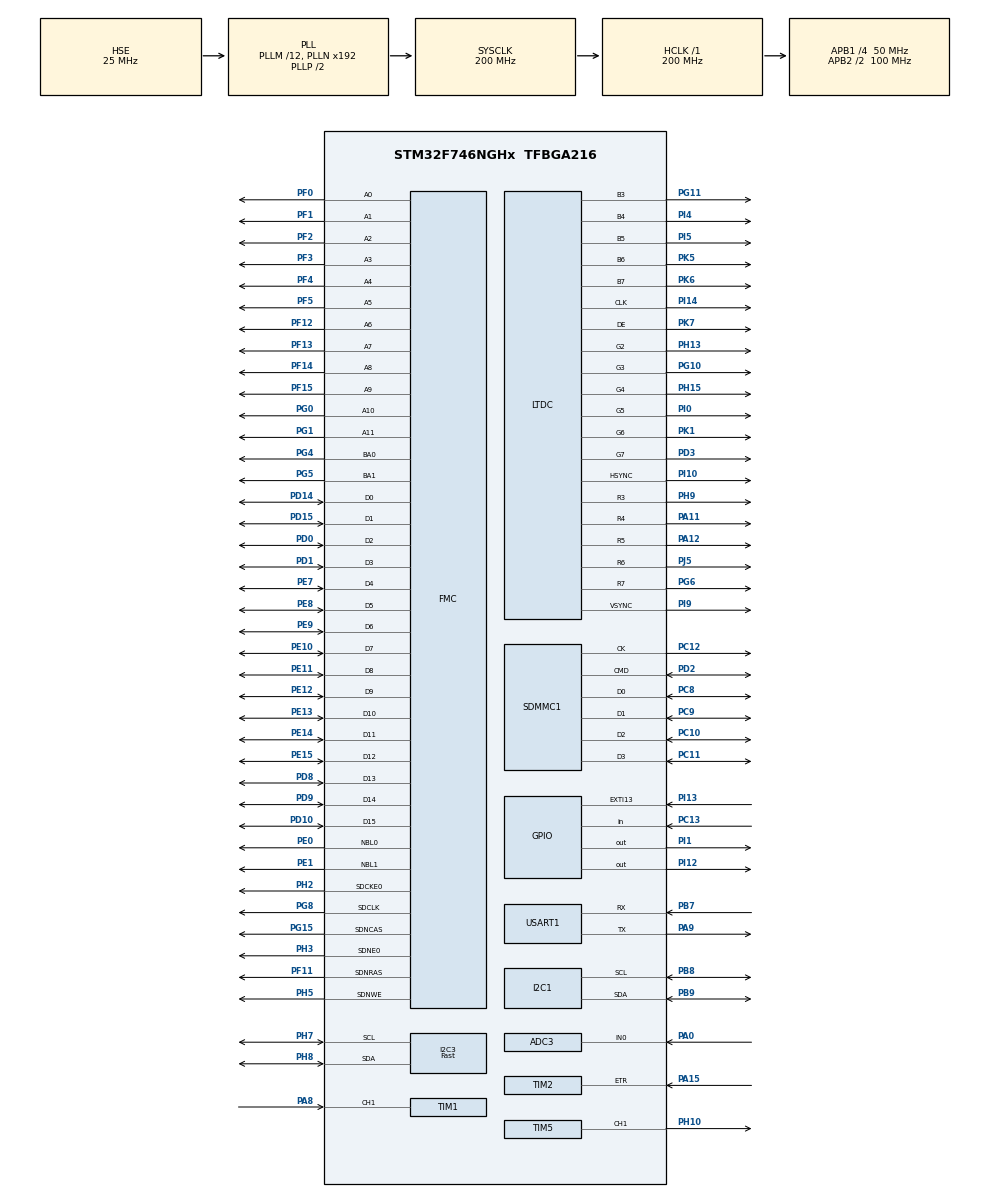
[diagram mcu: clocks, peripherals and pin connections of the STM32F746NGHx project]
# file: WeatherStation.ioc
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ADC3.Channel-0\#ChannelRegularConversion=ADC_CHANNEL_0
ADC3.ContinuousConvMode=ENABLE
ADC3.EOCSelection=ADC_EOC_SEQ_CONV
ADC3.NbrOfConversionFlag=1
ADC3.Rank-0\#ChannelRegularConversion=1
ADC3.SamplingTime-0\#ChannelRegularConversion=ADC_SAMPLETIME_3CYCLES
CORTEX_M7.ART_ACCLERATOR_ENABLE=1
Dma.Request0=SDMMC1_RX
Dma.Request1=SDMMC1_TX
Dma.SDMMC1_RX.0.Direction=DMA_PERIPH_TO_MEMORY
Dma.SDMMC1_RX.0.FIFOMode=DMA_FIFOMODE_ENABLE
Dma.SDMMC1_RX.0.FIFOThreshold=DMA_FIFO_THRESHOLD_FULL
Dma.SDMMC1_RX.0.Instance=DMA2_Stream3
Dma.SDMMC1_RX.0.MemBurst=DMA_MBURST_INC4
Dma.SDMMC1_RX.0.MemDataAlignment=DMA_MDATAALIGN_WORD
Dma.SDMMC1_RX.0.MemInc=DMA_MINC_ENABLE
Dma.SDMMC1_RX.0.Mode=DMA_PFCTRL
Dma.SDMMC1_RX.0.PeriphBurst=DMA_PBURST_INC4
Dma.SDMMC1_RX.0.PeriphDataAlignment=DMA_PDATAALIGN_WORD
Dma.SDMMC1_RX.0.PeriphInc=DMA_PINC_DISABLE
Dma.SDMMC1_RX.0.Priority=DMA_PRIORITY_LOW
Dma.SDMMC1_TX.1.Direction=DMA_MEMORY_TO_PERIPH
Dma.SDMMC1_TX.1.FIFOMode=DMA_FIFOMODE_ENABLE
Dma.SDMMC1_TX.1.FIFOThreshold=DMA_FIFO_THRESHOLD_FULL
Dma.SDMMC1_TX.1.Instance=DMA2_Stream6
Dma.SDMMC1_TX.1.MemBurst=DMA_MBURST_INC4
Dma.SDMMC1_TX.1.MemDataAlignment=DMA_MDATAALIGN_WORD
Dma.SDMMC1_TX.1.MemInc=DMA_MINC_ENABLE
Dma.SDMMC1_TX.1.Mode=DMA_PFCTRL
Dma.SDMMC1_TX.1.PeriphBurst=DMA_PBURST_INC4
Dma.SDMMC1_TX.1.PeriphDataAlignment=DMA_PDATAALIGN_WORD
Dma.SDMMC1_TX.1.PeriphInc=DMA_PINC_DISABLE
Dma.SDMMC1_TX.1.Priority=DMA_PRIORITY_LOW
FATFS.BSP.number=1
FATFS.USE_DMA_CODE_SD=1
FATFS0.BSP.STBoard=false
FATFS0.BSP.api=Unknown
FATFS0.BSP.i2caddr=0
FATFS0.BSP.instance=PC13
FATFS0.BSP.ip=GPIO
FATFS0.BSP.mode=Input
FATFS0.BSP.name=Detect_SDIO
FATFS0.BSP.solution=PC13
I2C1.Timing=0x00C0EAFF
I2C3.I2C_Speed_Mode=I2C_Fast
I2C3.Timing=0x00401959
Mcu.Family=STM32F7
Mcu.Name=STM32F746NGHx
Mcu.Package=TFBGA216
NVIC.DMA2_Stream3_IRQn=true\:0\:0\:false\:false\:true\:false\:true
NVIC.DMA2_Stream6_IRQn=true\:0\:0\:false\:false\:true\:false\:true
NVIC.EXTI15_10_IRQn=true\:11\:0\:true\:false\:true\:true\:true
NVIC.I2C3_EV_IRQn=true\:5\:0\:true\:false\:true\:true\:true
NVIC.PriorityGroup=NVIC_PRIORITYGROUP_4
NVIC.RTC_Alarm_IRQn=true\:14\:0\:true\:false\:true\:true\:true
NVIC.SDMMC1_IRQn=true\:0\:0\:false\:false\:true\:true\:true
NVIC.TIM1_CC_IRQn=true\:1\:0\:true\:false\:true\:true\:true
NVIC.TIM5_IRQn=true\:10\:0\:true\:false\:true\:true\:true
PA0/WKUP.Signal=ADCx_IN0
PA11.Mode=RGB565
PA11.Signal=LTDC_R4
PA12.Mode=RGB565
PA12.Signal=LTDC_R5
PA13.Mode=Serial_Wire
PA13.Signal=SYS_JTMS-SWDIO
PA14.Mode=Serial_Wire
PA14.Signal=SYS_JTCK-SWCLK
PA15.GPIO_PuPd=GPIO_PULLUP
PA15.Signal=S_TIM2_CH1_ETR
PA8.GPIO_PuPd=GPIO_PULLUP
PA8.Signal=S_TIM1_CH1
PA9.Mode=Asynchronous
PA9.Signal=USART1_TX
PB7.Mode=Asynchronous
PB7.Signal=USART1_RX
PB8.Mode=I2C
PB8.Signal=I2C1_SCL
PB9.Mode=I2C
PB9.Signal=I2C1_SDA
PC10.Mode=SD_4_bits_Wide_bus
PC10.Signal=SDMMC1_D2
PC11.Mode=SD_4_bits_Wide_bus
PC11.Signal=SDMMC1_D3
PC12.Mode=SD_4_bits_Wide_bus
PC12.Signal=SDMMC1_CK
PC13.Signal=GPIO_Input
PC8.Mode=SD_4_bits_Wide_bus
PC8.Signal=SDMMC1_D0
PC9.Mode=SD_4_bits_Wide_bus
PC9.Signal=SDMMC1_D1
PD0.Signal=FMC_D2_DA2
PD1.Signal=FMC_D3_DA3
PD10.Signal=FMC_D15_DA15
PD14.Signal=FMC_D0_DA0
PD15.Signal=FMC_D1_DA1
PD2.Mode=SD_4_bits_Wide_bus
PD2.Signal=SDMMC1_CMD
PD3.Mode=RGB565
PD3.Signal=LTDC_G7
PD8.Signal=FMC_D13_DA13
PD9.Signal=FMC_D14_DA14
PE0.Signal=FMC_NBL0
PE1.Signal=FMC_NBL1
PE10.Signal=FMC_D7_DA7
PE11.Signal=FMC_D8_DA8
PE12.Signal=FMC_D9_DA9
PE13.Signal=FMC_D10_DA10
PE14.Signal=FMC_D11_DA11
PE15.Signal=FMC_D12_DA12
PE7.Signal=FMC_D4_DA4
PE8.Signal=FMC_D5_DA5
PE9.Signal=FMC_D6_DA6
PF0.Signal=FMC_A0
PF1.Signal=FMC_A1
PF11.Signal=FMC_SDNRAS
PF12.Signal=FMC_A6
PF13.Signal=FMC_A7
PF14.Signal=FMC_A8
PF15.Signal=FMC_A9
PF2.Signal=FMC_A2
PF3.Signal=FMC_A3
PF4.Signal=FMC_A4
PF5.Signal=FMC_A5
PG0.Signal=FMC_A10
PG1.Signal=FMC_A11
PG10.Mode=RGB565
PG10.Signal=LTDC_G3
PG11.Mode=RGB565
PG11.Signal=LTDC_B3
PG15.Signal=FMC_SDNCAS
PG4.Signal=FMC_A14_BA0
PG5.Signal=FMC_A15_BA1
PG6.Mode=RGB565
PG6.Signal=LTDC_R7
PG8.Signal=FMC_SDCLK
PH0/OSC_IN.Mode=HSE-External-Oscillator
PH0/OSC_IN.Signal=RCC_OSC_IN
PH1/OSC_OUT.Mode=HSE-External-Oscillator
PH1/OSC_OUT.Signal=RCC_OSC_OUT
PH10.Signal=S_TIM5_CH1
PH13.Mode=RGB565
PH13.Signal=LTDC_G2
PH15.Mode=RGB565
PH15.Signal=LTDC_G4
PH2.Mode=SdramChipSelect1_1
PH2.Signal=FMC_SDCKE0
PH3.Mode=SdramChipSelect1_1
PH3.Signal=FMC_SDNE0
PH5.Signal=FMC_SDNWE
PH7.Mode=I2C
PH7.Signal=I2C3_SCL
PH8.Mode=I2C
PH8.Signal=I2C3_SDA
PH9.Mode=RGB565
PH9.Signal=LTDC_R3
PI0.Mode=RGB565
PI0.Signal=LTDC_G5
PI1.Signal=GPIO_Output
PI10.Mode=RGB565
PI10.Signal=LTDC_HSYNC
PI12.PinState=GPIO_PIN_SET
PI12.Signal=GPIO_Output
PI13.Signal=GPXTI13
PI14.Mode=RGB565
PI14.Signal=LTDC_CLK
PI4.Mode=RGB565
PI4.Signal=LTDC_B4
PI5.Mode=RGB565
PI5.Signal=LTDC_B5
PI9.Mode=RGB565
PI9.Signal=LTDC_VSYNC
PJ5.Mode=RGB565
PJ5.Signal=LTDC_R6
PK1.Mode=RGB565
PK1.Signal=LTDC_G6
PK5.Mode=RGB565
PK5.Signal=LTDC_B6
PK6.Mode=RGB565
PK6.Signal=LTDC_B7
PK7.Mode=RGB565
PK7.Signal=LTDC_DE
ProjectManager.HeapSize=0x200
ProjectManager.StackSize=0x400
ProjectManager.TargetToolchain=STM32CubeIDE
RCC.AHBFreq_Value=200000000
RCC.APB1CLKDivider=RCC_HCLK_DIV4
RCC.APB1Freq_Value=50000000
RCC.APB1TimFreq_Value=100000000
RCC.APB2CLKDivider=RCC_HCLK_DIV2
RCC.APB2Freq_Value=100000000
RCC.APB2TimFreq_Value=200000000
RCC.CortexFreq_Value=200000000
RCC.HCLKFreq_Value=200000000
RCC.HSE_VALUE=25000000
RCC.HSI_VALUE=16000000
RCC.LSE_VALUE=32768
RCC.PLLM=12
RCC.PLLQ=8
RCC.PLLSAIN=72
RCC.PLLSAIR=3
RCC.PLLSourceVirtual=RCC_PLLSOURCE_HSE
RCC.SDMMCClockSelection=RCC_SDMMC1CLKSOURCE_CLK48
RCC.SYSCLKFreq_VALUE=200000000
RCC.SYSCLKSource=RCC_SYSCLKSOURCE_PLLCLK
RCC.USBFreq_Value=50000000
RCC.VCOOutputFreq_Value=400000000
RTC.Alarm-Alarm\ A=RTC_ALARM_A
RTC.AlarmMaskDateWeekDay-Alarm\ A=RTC_ALARMMASK_DATEWEEKDAY
RTC.AlarmMaskHours-Alarm\ A=RTC_ALARMMASK_HOURS
RTC.AlarmMaskMinutes-Alarm\ A=RTC_ALARMMASK_MINUTES
RTC.Format=RTC_FORMAT_BIN
RTC.Minutes_A-Alarm\ A=0
RTC.Month=RTC_MONTH_JANUARY
RTC.Seconds_A-Alarm\ A=0
RTC.WeekDay=RTC_WEEKDAY_MONDAY
RTC.Year=21
SH.ADCx_IN0.0=ADC3_IN0,IN0
SH.FMC_A0.0=FMC_A0,12b-sda1
SH.FMC_A1.0=FMC_A1,12b-sda1
SH.FMC_A10.0=FMC_A10,12b-sda1
SH.FMC_A11.0=FMC_A11,12b-sda1
SH.FMC_A14_BA0.0=FMC_BA0,FourSdramBanks1
SH.FMC_A15_BA1.0=FMC_BA1,FourSdramBanks1
SH.FMC_A2.0=FMC_A2,12b-sda1
SH.FMC_A3.0=FMC_A3,12b-sda1
SH.FMC_A4.0=FMC_A4,12b-sda1
SH.FMC_A5.0=FMC_A5,12b-sda1
SH.FMC_A6.0=FMC_A6,12b-sda1
SH.FMC_A7.0=FMC_A7,12b-sda1
SH.FMC_A8.0=FMC_A8,12b-sda1
SH.FMC_A9.0=FMC_A9,12b-sda1
SH.FMC_D0_DA0.0=FMC_D0,sd-16b-d1
SH.FMC_D10_DA10.0=FMC_D10,sd-16b-d1
SH.FMC_D11_DA11.0=FMC_D11,sd-16b-d1
SH.FMC_D12_DA12.0=FMC_D12,sd-16b-d1
SH.FMC_D13_DA13.0=FMC_D13,sd-16b-d1
SH.FMC_D14_DA14.0=FMC_D14,sd-16b-d1
SH.FMC_D15_DA15.0=FMC_D15,sd-16b-d1
SH.FMC_D1_DA1.0=FMC_D1,sd-16b-d1
SH.FMC_D2_DA2.0=FMC_D2,sd-16b-d1
SH.FMC_D3_DA3.0=FMC_D3,sd-16b-d1
SH.FMC_D4_DA4.0=FMC_D4,sd-16b-d1
SH.FMC_D5_DA5.0=FMC_D5,sd-16b-d1
SH.FMC_D6_DA6.0=FMC_D6,sd-16b-d1
SH.FMC_D7_DA7.0=FMC_D7,sd-16b-d1
SH.FMC_D8_DA8.0=FMC_D8,sd-16b-d1
SH.FMC_D9_DA9.0=FMC_D9,sd-16b-d1
SH.FMC_NBL0.0=FMC_NBL0,Sd2ByteEnable1
SH.FMC_NBL1.0=FMC_NBL1,Sd2ByteEnable1
SH.FMC_SDCLK.0=FMC_SDCLK,12b-sda1
SH.FMC_SDNCAS.0=FMC_SDNCAS,12b-sda1
SH.FMC_SDNRAS.0=FMC_SDNRAS,12b-sda1
SH.FMC_SDNWE.0=FMC_SDNWE,12b-sda1
SH.S_TIM1_CH1.0=TIM1_CH1,Input_Capture1_from_TI1
SH.S_TIM2_CH1_ETR.0=TIM2_ETR,TriggerSource_ETR
SH.S_TIM5_CH1.0=TIM5_CH1,Output Compare1 CH1
TIM1.Channel-Input_Capture1_from_TI1=TIM_CHANNEL_1
TIM1.Period=10799
TIM1.Prescaler=29
TIM5.Channel-Output\ Compare1\ CH1=TIM_CHANNEL_1
TIM5.Period=999999
TIM5.Prescaler=999
USART1.VirtualMode-Asynchronous=VM_ASYNC
VP_DMA2D_VS_DMA2D.Mode=DMA2D_Activate
VP_FATFS_VS_SDIO.Mode=SDIO
VP_RTC_VS_RTC_Activate.Mode=RTC_Enabled
VP_RTC_VS_RTC_Alarm_A_Intern.Mode=Alarm A
VP_RTC_VS_RTC_Calendar.Mode=RTC_Calendar
VP_TIM1_VS_ClockSourceINT.Mode=Internal
VP_TIM2_VS_ControllerModeClock.Mode=Clock Mode
board=STM32F746G-DISCO

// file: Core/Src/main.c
/* USER CODE BEGIN Header */
/**
 ******************************************************************************
 * @file           : main.c
 * @brief          : Main program body
 ******************************************************************************
 * @attention
 *
 * <h2><center>&copy; Copyright (c) 2021 STMicroelectronics.
 * All rights reserved.</center></h2>
 *
 * This software component is licensed by ST under BSD 3-Clause license,
 * the "License"; You may not use this file except in compliance with the
 * License. You may obtain a copy of the License at:
 *                        opensource.org/licenses/BSD-3-Clause
 *
 * @author : Benjamin Chevais
 *
 ******************************************************************************
 */
/* USER CODE END Header */
#include <DrawFrameGraph.h>
#include <I2CSensors.h>
#include "main.h"
#include "adc.h"
#include "dma.h"
#include "dma2d.h"
#include "fatfs.h"
#include "i2c.h"
#include "ltdc.h"
#include "rtc.h"
#include "sdmmc.h"
#include "tim.h"
#include "usart.h"
#include "gpio.h"
#include "fmc.h"

/* USER CODE BEGIN Includes */

#include <stdio.h>
#include <string.h>
#include "WeatherStation.h"
#include "WindSpeed.h"
#include "WindDirection.h"
#include "Pressure.h"
#include "RainGauge.h"
#include "Sd.h"

#ifdef __GNUC__
/* With GCC/RAISONANCE, small printf (option LD Linker->Libraries->Small printf
set to 'Yes') calls __io_putchar() */
#define PUTCHAR_PROTOTYPE int __io_putchar(int ch)
#else
#define PUTCHAR_PROTOTYPE int fputc(int ch, FILE *f)
#endif /* __GNUC__ */
/* USER CODE END Includes */

/* USER CODE BEGIN PV */
int DELAY = 5;
double WIND_TICK = 0;
int alarmA_sdcard = 0;
acquisition_flag = 0; // define in main.h

RTC_DateTypeDef sDate;
RTC_TimeTypeDef sTime;

/* USER CODE END PV */

void SystemClock_Config(void);

int main(void)
{

  /* MCU Configuration--------------------------------------------------------*/

  /* Reset of all peripherals, Initializes the Flash interface and the Systick. */
  HAL_Init();

  /* Configure the system clock */
  SystemClock_Config();

  /* Initialize all configured peripherals */
  MX_GPIO_Init();
  MX_DMA2D_Init();
  MX_FMC_Init();
  MX_I2C3_Init();
  MX_LTDC_Init();
  MX_USART1_UART_Init();
  MX_I2C1_Init();
  MX_TIM5_Init();
  MX_ADC3_Init();
  MX_TIM1_Init();
  MX_TIM2_Init();
  MX_DMA_Init();
  MX_SDMMC1_SD_Init();
  MX_RTC_Init();
  MX_FATFS_Init();
  /* USER CODE BEGIN 2 */

	WeatherStationInit(); // initialize the global variables

	init_screen(); // Initialize the screen

	RaingaugeStart(&htim2); // Timer of rain
	HAL_TIM_OC_Start_IT(&htim5, TIM_CHANNEL_1); // Aggregation Timer
	HAL_TIM_IC_Start_IT(&htim1,TIM_CHANNEL_1); // Wind speed Timer
	HAL_RTC_Init(&hrtc); // RTC launch / AlarmA for the SD card
	HAL_ADC_Start(&hadc3); // Starts conversion Analog to Digital.
	initSD(); // Initialize the sd card

	printf("démarrage du programme !\r\n\n");

	display_home(); // Display the home screen

  /* USER CODE END 2 */

  /* Infinite loop */
	while (1)
	{

    /* USER CODE BEGIN 3 */
		HAL_RTC_GetDate(&hrtc, &sDate, RTC_FORMAT_BIN);
		HAL_RTC_GetTime(&hrtc, &sTime, RTC_FORMAT_BIN);

		if(acquisition_flag == 1) {
			aggregate();
			acquisition_flag = 0;
		}

		if(alarmA_sdcard == 1) {
			saveSD();
			alarmA_sdcard = 0;
		}
		/*
	  HAL_GPIO_TogglePin (GPIOI, GPIO_PIN_1);
	  HAL_Delay (1000);
		 */
	}
  /* USER CODE END 3 */
}

void SystemClock_Config(void)
{
  RCC_OscInitTypeDef RCC_OscInitStruct = {0};
  RCC_ClkInitTypeDef RCC_ClkInitStruct = {0};
  RCC_PeriphCLKInitTypeDef PeriphClkInitStruct = {0};

  /** Configure the main internal regulator output voltage
  */
  __HAL_RCC_PWR_CLK_ENABLE();
  __HAL_PWR_VOLTAGESCALING_CONFIG(PWR_REGULATOR_VOLTAGE_SCALE1);
  /** Initializes the RCC Oscillators according to the specified parameters
  * in the RCC_OscInitTypeDef structure.
  */
  RCC_OscInitStruct.OscillatorType = RCC_OSCILLATORTYPE_LSI|RCC_OSCILLATORTYPE_HSE;
  RCC_OscInitStruct.HSEState = RCC_HSE_ON;
  RCC_OscInitStruct.LSIState = RCC_LSI_ON;
  RCC_OscInitStruct.PLL.PLLState = RCC_PLL_ON;
  RCC_OscInitStruct.PLL.PLLSource = RCC_PLLSOURCE_HSE;
  RCC_OscInitStruct.PLL.PLLM = 12;
  RCC_OscInitStruct.PLL.PLLN = 192;
  RCC_OscInitStruct.PLL.PLLP = RCC_PLLP_DIV2;
  RCC_OscInitStruct.PLL.PLLQ = 8;
  if (HAL_RCC_OscConfig(&RCC_OscInitStruct) != HAL_OK)
  {
    Error_Handler();
  }
  /** Activate the Over-Drive mode
  */
  if (HAL_PWREx_EnableOverDrive() != HAL_OK)
  {
    Error_Handler();
  }
  /** Initializes the CPU, AHB and APB buses clocks
  */
  RCC_ClkInitStruct.ClockType = RCC_CLOCKTYPE_HCLK|RCC_CLOCKTYPE_SYSCLK
                              |RCC_CLOCKTYPE_PCLK1|RCC_CLOCKTYPE_PCLK2;
  RCC_ClkInitStruct.SYSCLKSource = RCC_SYSCLKSOURCE_PLLCLK;
  RCC_ClkInitStruct.AHBCLKDivider = RCC_SYSCLK_DIV1;
  RCC_ClkInitStruct.APB1CLKDivider = RCC_HCLK_DIV4;
  RCC_ClkInitStruct.APB2CLKDivider = RCC_HCLK_DIV2;

  if (HAL_RCC_ClockConfig(&RCC_ClkInitStruct, FLASH_LATENCY_6) != HAL_OK)
  {
    Error_Handler();
  }
  PeriphClkInitStruct.PeriphClockSelection = RCC_PERIPHCLK_LTDC|RCC_PERIPHCLK_RTC
                              |RCC_PERIPHCLK_USART1|RCC_PERIPHCLK_I2C1
                              |RCC_PERIPHCLK_I2C3|RCC_PERIPHCLK_SDMMC1
                              |RCC_PERIPHCLK_CLK48;
  PeriphClkInitStruct.PLLSAI.PLLSAIN = 72;
  PeriphClkInitStruct.PLLSAI.PLLSAIR = 3;
  PeriphClkInitStruct.PLLSAI.PLLSAIQ = 2;
  PeriphClkInitStruct.PLLSAI.PLLSAIP = RCC_PLLSAIP_DIV2;
  PeriphClkInitStruct.PLLSAIDivQ = 1;
  PeriphClkInitStruct.PLLSAIDivR = RCC_PLLSAIDIVR_2;
  PeriphClkInitStruct.RTCClockSelection = RCC_RTCCLKSOURCE_LSI;
  PeriphClkInitStruct.Usart1ClockSelection = RCC_USART1CLKSOURCE_PCLK2;
  PeriphClkInitStruct.I2c1ClockSelection = RCC_I2C1CLKSOURCE_PCLK1;
  PeriphClkInitStruct.I2c3ClockSelection = RCC_I2C3CLKSOURCE_PCLK1;
  PeriphClkInitStruct.Clk48ClockSelection = RCC_CLK48SOURCE_PLL;
  PeriphClkInitStruct.Sdmmc1ClockSelection = RCC_SDMMC1CLKSOURCE_CLK48;
  if (HAL_RCCEx_PeriphCLKConfig(&PeriphClkInitStruct) != HAL_OK)
  {
    Error_Handler();
  }
}

/* USER CODE BEGIN 4 */
PUTCHAR_PROTOTYPE
{
	/* Place your implementation of fputc here */
	/* e.g. write a character to the USART2 and Loop until the end of transmission */
	HAL_UART_Transmit(&huart1, (uint8_t *)&ch, 1, 100);

	return ch;
}

void HAL_TIM_IC_CaptureCallback(TIM_HandleTypeDef *htim)
{
	if (htim->Instance==TIM1)
	{
		WIND_TICK++;
	}
}

void HAL_RTC_AlarmAEventCallback(RTC_HandleTypeDef *hrtc)
{
	printf("Alarm A !\r\n\n");
	alarmA_sdcard = 1;
}

void displayWeatherStation(T_WeatherStation ws) {

	printf("|| ================ || \r\n");
	printf("temp :%f \r\n", (double)ws.temperature);
	printf("hum : %f \r\n", (double)ws.humidity);
	printf("press : %f \r\n", (double)ws.pressure);
	printf("rain : %f \r\n", (double)ws.rainfall);
	printf("wspeed : %f \r\n", (double)ws.wind_speed);
	printf("wdir : %f \r\n", (double)ws.wind_direction);
	printf("|| ================ || \r\n");

}

void aggregate() {

	double temperature = captureTemp();
	double humidity = captureHumidity();
	double pressure = capturePressure();
	double rainfall = captureRainfall(&htim2);
	double wspeed = captureWindspeed(&WIND_TICK, DELAY);
	double wdir = captureDirection(HAL_ADC_GetValue(&hadc3));

	T_Time time = getTime();
	displayTime(time);

	updateWeatherStation(&Weather_station, &Graphics_data, &Data_to_save, temperature, humidity, pressure, rainfall, wspeed, wdir, time);

	//displayWeatherStation(Weather_station);

	update_screen();
}

/* USER CODE END 4 */

void Error_Handler(void)
{
  /* USER CODE BEGIN Error_Handler_Debug */
	/* User can add his own implementation to report the HAL error return state */
	printf("error\r\n");
  /* USER CODE END Error_Handler_Debug */
}

/************************ (C) COPYRIGHT STMicroelectronics *****END OF FILE****/
